# MSP432P411V register map
Vendor: Texas Instruments; File version: 3.230
Registers are 32-bit, read-write, reset 0x0 unless marked. A register's access mark holds for its fields unless they carry their own. Offsets are from the block's base; [hi:lo] are bit positions.

## PCM
Base 0x40010000
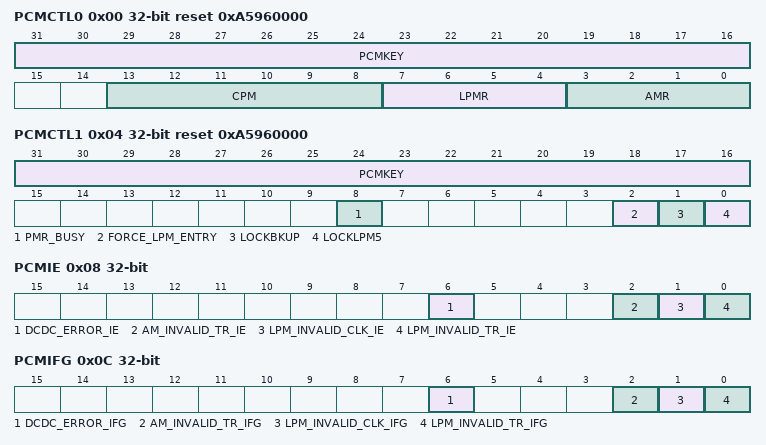
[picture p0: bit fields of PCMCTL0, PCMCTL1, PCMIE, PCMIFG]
0x00 PCMCTL0 reset 0xA5960000 — Control 0 Register
  [31:16] PCMKEY
  [13:8] CPM ro — Current Power Mode
    on read: 0=LDO based Active Mode at Core voltage setting 0; 1=LDO based Active Mode at Core voltage setting 1; 4=DC-DC based Active Mode at Core voltage setting 0; 5=DC-DC based Active Mode at Core voltage setting 1; 8=Low-Frequency Active Mode at Core voltage setting 0; 9=Low-Frequency Active Mode at Core voltage setting 1; 16=LDO based LPM0 at Core voltage setting 0; 17=LDO based LPM0 at Core voltage setting 1; 20=DC-DC based LPM0 at Core voltage setting 0; 21=DC-DC based LPM0 at Core voltage setting 1; 24=Low-Frequency LPM0 at Core voltage setting 0; 25=Low-Frequency LPM0 at Core voltage setting 1; 32=LPM3
  [7:4] LPMR — Low Power Mode Request
    0=LPM3. Core voltage setting is similar to the mode from which LPM3 is entered.; 10=LPM3.5. Core voltage setting 0.; 12=LPM4.5
  [3:0] AMR — Active Mode Request
    0=LDO based Active Mode at Core voltage setting 0; 1=LDO based Active Mode at Core voltage setting 1; 4=DC-DC based Active Mode at Core voltage setting 0; 5=DC-DC based Active Mode at Core voltage setting 1; 8=Low-Frequency Active Mode at Core voltage setting 0; 9=Low-Frequency Active Mode at Core voltage setting 1
0x04 PCMCTL1 reset 0xA5960000 — Control 1 Register
  [31:16] PCMKEY
  [8] PMR_BUSY — Power mode request busy flag
  [2] FORCE_LPM_ENTRY
    0=PCM aborts LPM3/LPMx.5 transition if the active clock configuration does not meet the LPM3/LPMx.5 entry criteria. PCM generates the LPM_INVALID_CLK flag on abort to LPM3/LPMx.5 entry.; 1=PCM enters LPM3/LPMx.5 after shuting off the clocks forcefully. Application needs to ensure RTC and WDT are clocked using BCLK tree to keep these modules alive in LPM3/LPM3.5. In LPM4.5 all clocks are forcefully shutoff and the core voltage is turned off.
  [1] LOCKBKUP — Lock Backup
    0=Backup domain configuration defaults to reset condition; 1=Backup domain configuration remains locked during LPM3.5 entry and exit
  [0] LOCKLPM5
    0=LPMx.5 configuration defaults to reset condition; 1=LPMx.5 configuration remains locked during LPMx.5 entry and exit
0x08 PCMIE — Interrupt Enable Register
  [all] fields
    0=Disabled; 1=Enabled
  [6] DCDC_ERROR_IE — DC-DC error interrupt enable
  [2] AM_INVALID_TR_IE — Active mode invalid transition interrupt enable
  [1] LPM_INVALID_CLK_IE — LPM invalid clock interrupt enable
  [0] LPM_INVALID_TR_IE — LPM invalid transition interrupt enable
0x0C PCMIFG ro — Interrupt Flag Register
  [6] DCDC_ERROR_IFG — DC-DC error flag
  [2] AM_INVALID_TR_IFG — Active mode invalid transition flag
  [1] LPM_INVALID_CLK_IFG — LPM invalid clock flag
  [0] LPM_INVALID_TR_IFG — LPM invalid transition flag
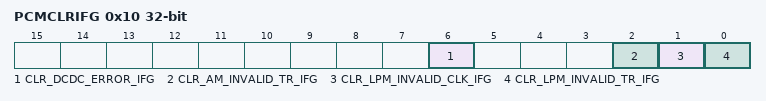
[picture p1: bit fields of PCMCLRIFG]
0x10 PCMCLRIFG wo — Clear Interrupt Flag Register
  [6] CLR_DCDC_ERROR_IFG — Clear DC-DC error flag
  [2] CLR_AM_INVALID_TR_IFG — Clear active mode invalid transition flag
  [1] CLR_LPM_INVALID_CLK_IFG — Clear LPM invalid clock flag
  [0] CLR_LPM_INVALID_TR_IFG — Clear LPM invalid transition flag

## PSS
Base 0x40010800
0x00 PSSKEY reset 0xA596 — Key Register
  [15:0] PSSKEY — PSS control key
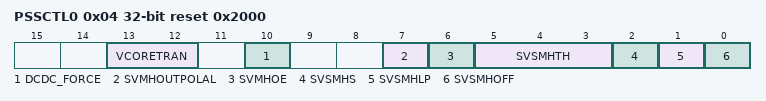
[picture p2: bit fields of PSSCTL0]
0x04 PSSCTL0 reset 0x2000 — Control 0 Register
  [13:12] VCORETRAN — Controls core voltage level transition time
    0=32 s / 100 mV; 1=64 s / 100 mV; 2=128 s / 100 mV (default); 3=256 s / 100 mV
  [10] DCDC_FORCE — Force DC-DC regulator operation
    0=DC-DC regulator operation not forced. Automatic fail-safe mechanism switches the core voltage regulator from DC-DC to LDO when the supply voltage falls below the minimum supply voltage necessary for DC-DC operation.; 1=DC-DC regulator operation forced. Automatic fail-safe mechanism is disabled and device continues to operate out of DC-DC regulator.
  [7] SVMHOUTPOLAL — SVMHOUT pin polarity active low
    0=SVMHOUT is active high. An error condition is signaled by a 1 at the SVMHOUT pin; 1=SVMHOUT is active low. An error condition is signaled by a 0 at the SVMHOUT pin
  [6] SVMHOE — SVSM high-side output enable
    0=SVSMHIFG bit is not output; 1=SVSMHIFG bit is output to the device SVMHOUT pin. The device-specific port logic must be configured accordingly
  [5:3] SVSMHTH — SVSM high-side reset voltage level
  [2] SVSMHS — Supply supervisor or monitor selection for the high-side
    0=Configure as SVSH; 1=Configure as SVMH
  [1] SVSMHLP — SVSM high-side low power normal performance mode
    0=Full performance mode. See the device-specific data sheet for response times.; 1=Low power normal performance mode in LPM3, LPM4, and LPMx.5, full performance in all other modes. See the device-specific data sheet for response times.
  [0] SVSMHOFF — SVSM high-side off
    0=The SVSMH is on; 1=The SVSMH is off
0x34 PSSIE — Interrupt Enable Register
  [1] SVSMHIE — High-side SVSM interrupt enable
    0=Interrupt disabled; 1=Interrupt enabled
0x38 PSSIFG ro — Interrupt Flag Register
  [1] SVSMHIFG — High-side SVSM interrupt flag
    on read: 0=No interrupt pending; 1=Interrupt due to SVSMH
0x3C PSSCLRIFG — Clear Interrupt Flag Register
  [1] CLRSVSMHIFG wo — SVSMH clear interrupt flag
    on write: 0=No effect; 1=Clear pending interrupt flag
